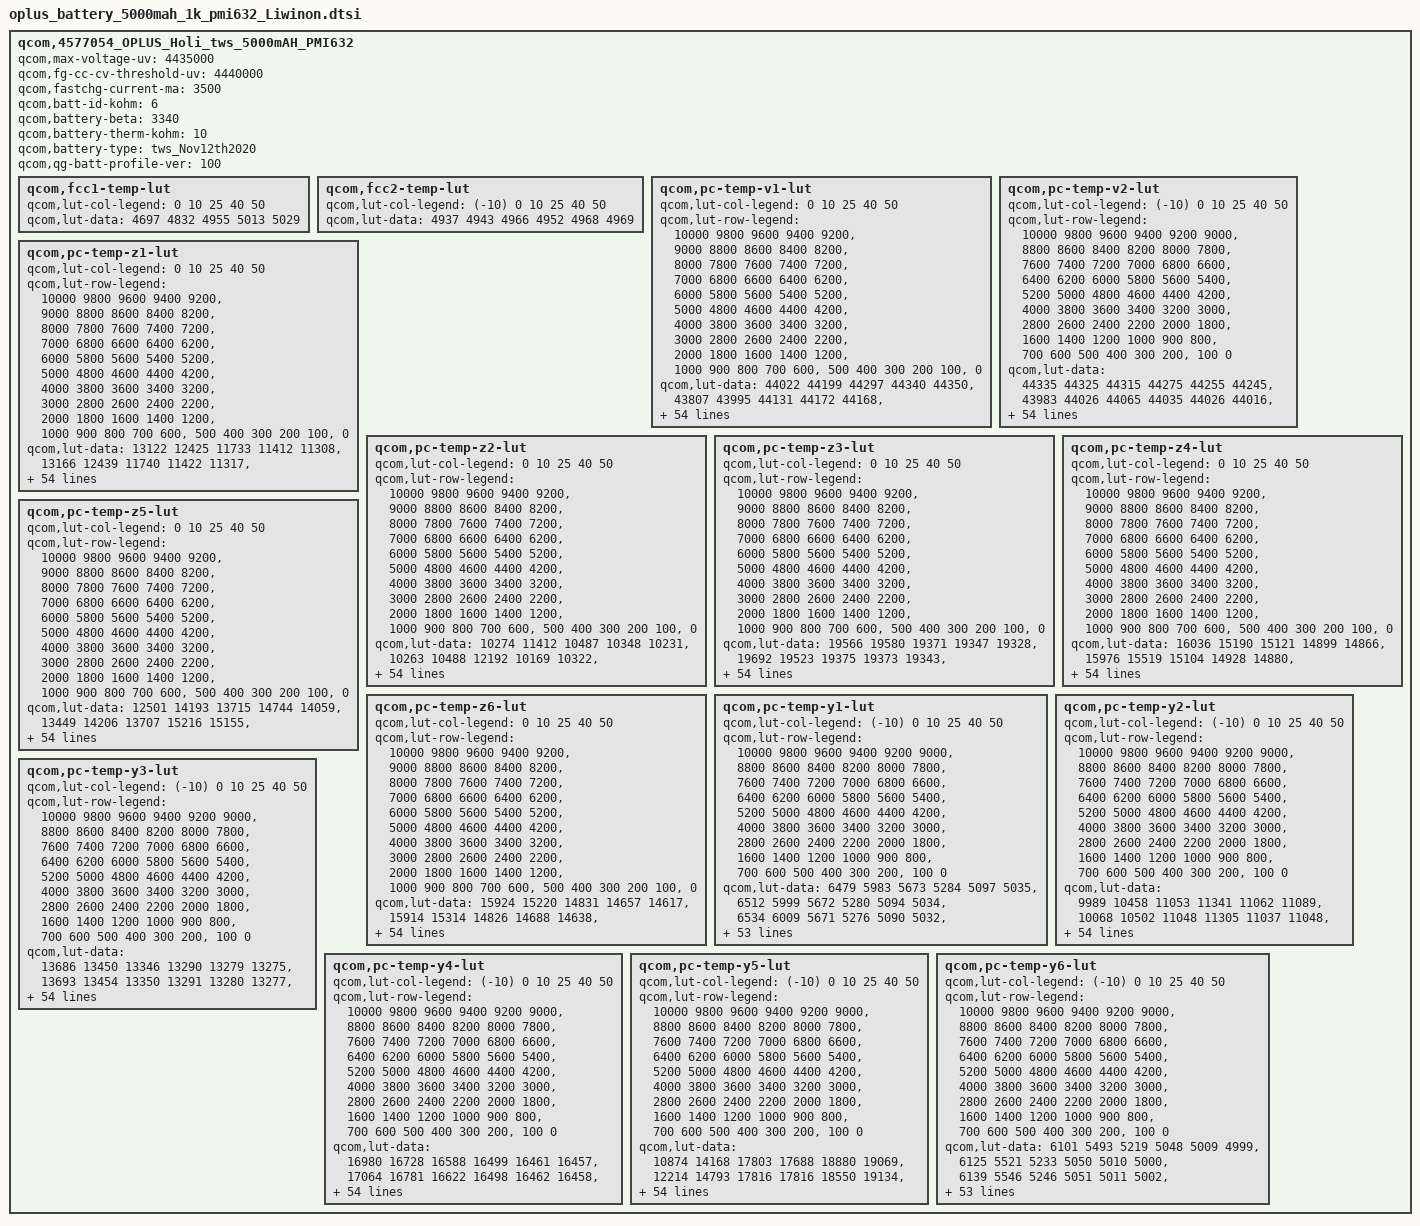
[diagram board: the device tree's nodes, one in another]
qcom,4577054_OPLUS_Holi_tws_5000mAH_PMI632 {
    /* 4577054_OPLUS_Holi_tws_5000mAH_PMI632_averaged_MasterSlave_Nov12th2020 */
    qcom,max-voltage-uv = <4435000>;
    qcom,fg-cc-cv-threshold-uv = <4440000>;
    qcom,fastchg-current-ma = <3500>;
    //qcom,batt-id-kohm = <1>;
    qcom,batt-id-kohm = <6>;
    qcom,battery-beta = <3340>;
    qcom,battery-therm-kohm = <10>;
    qcom,battery-type = "tws_Nov12th2020";
    qcom,qg-batt-profile-ver = <100>;
    //qcom,jeita-soft-thresholds_oplus = <0x5E68 0x72A>;
    //qcom,jeita-hard-thresholds_oplus = <0x5E68 0x72A>;

	qcom,fcc1-temp-lut {
		qcom,lut-col-legend = <0 10 25 40 50>;
		qcom,lut-data = <4697 4832 4955 5013 5029>;
	};

	qcom,fcc2-temp-lut {
		qcom,lut-col-legend = <(-10) 0 10 25 40 50>;
		qcom,lut-data = <4937 4943 4966 4952 4968 4969>;
	};

	qcom,pc-temp-v1-lut {
		qcom,lut-col-legend = <0 10 25 40 50>;
		qcom,lut-row-legend = <10000 9800 9600 9400 9200>,
			<9000 8800 8600 8400 8200>,
			<8000 7800 7600 7400 7200>,
			<7000 6800 6600 6400 6200>,
			<6000 5800 5600 5400 5200>,
			<5000 4800 4600 4400 4200>,
			<4000 3800 3600 3400 3200>,
			<3000 2800 2600 2400 2200>,
			<2000 1800 1600 1400 1200>,
			<1000 900 800 700 600>,
			<500 400 300 200 100>,
			<0>;
		qcom,lut-data = <44022 44199 44297 44340 44350>,
			<43807 43995 44131 44172 44168>,
			<43584 43790 43947 43979 43983>,
			<43355 43581 43746 43782 43791>,
			<43119 43359 43527 43585 43590>,
			<42881 43123 43299 43376 43379>,
			<42641 42883 43061 43145 43155>,
			<42401 42642 42818 42900 42918>,
			<42166 42398 42575 42654 42678>,
			<41935 42157 42330 42407 42433>,
			<41707 41919 42085 42162 42188>,
			<41482 41685 41841 41923 41947>,
			<41260 41458 41601 41688 41709>,
			<41046 41234 41369 41453 41474>,
			<40841 41018 41146 41217 41241>,
			<40640 40811 40929 40990 41014>,
			<40437 40609 40720 40777 40795>,
			<40232 40411 40517 40574 40583>,
			<40042 40219 40325 40378 40383>,
			<39879 40031 40142 40195 40203>,
			<39730 39855 39947 39996 40013>,
			<39579 39680 39733 39732 39759>,
			<39425 39471 39511 39437 39464>,
			<39270 39201 39272 39221 39244>,
			<39108 38966 39022 39063 39091>,
			<38937 38820 38851 38931 38962>,
			<38788 38707 38753 38816 38842>,
			<38674 38621 38674 38715 38735>,
			<38578 38554 38590 38616 38628>,
			<38504 38498 38508 38520 38520>,
			<38447 38444 38431 38430 38420>,
			<38400 38394 38358 38345 38332>,
			<38360 38347 38289 38266 38252>,
			<38328 38300 38226 38193 38177>,
			<38295 38256 38169 38126 38107>,
			<38261 38212 38114 38061 38037>,
			<38225 38171 38067 38002 37969>,
			<38178 38122 38019 37942 37899>,
			<38110 38051 37950 37866 37813>,
			<38026 37959 37855 37767 37707>,
			<37919 37854 37750 37658 37591>,
			<37780 37726 37637 37547 37476>,
			<37627 37580 37507 37421 37348>,
			<37461 37409 37341 37259 37187>,
			<37320 37251 37191 37117 37049>,
			<37230 37157 37090 37023 36967>,
			<37202 37125 37064 36999 36938>,
			<37168 37104 37048 36980 36922>,
			<37136 37081 37024 36962 36900>,
			<37075 37038 36978 36909 36838>,
			<36874 36827 36767 36668 36576>,
			<36420 36383 36333 36232 36138>,
			<35835 35810 35760 35661 35566>,
			<35044 35022 34978 34876 34781>,
			<33766 33770 33759 33655 33559>,
			<30000 30000 30000 30000 30000>;
	};

	qcom,pc-temp-v2-lut {
		qcom,lut-col-legend = <(-10) 0 10 25 40 50>;
		qcom,lut-row-legend = <10000 9800 9600 9400 9200 9000>,
			<8800 8600 8400 8200 8000 7800>,
			<7600 7400 7200 7000 6800 6600>,
			<6400 6200 6000 5800 5600 5400>,
			<5200 5000 4800 4600 4400 4200>,
			<4000 3800 3600 3400 3200 3000>,
			<2800 2600 2400 2200 2000 1800>,
			<1600 1400 1200 1000 900 800>,
			<700 600 500 400 300 200>,
			<100 0>;
		qcom,lut-data = <44335 44325 44315 44275 44255 44245>,
			<43983 44026 44065 44035 44026 44016>,
			<43662 43750 43827 43802 43801 43792>,
			<43376 43500 43600 43579 43583 43576>,
			<43124 43280 43388 43366 43372 43368>,
			<42877 43056 43170 43149 43157 43154>,
			<42611 42810 42933 42913 42924 42923>,
			<42344 42555 42687 42669 42683 42683>,
			<42106 42301 42439 42425 42442 42442>,
			<41897 42044 42189 42181 42197 42199>,
			<41688 41798 41942 41939 41954 41956>,
			<41456 41572 41701 41700 41716 41716>,
			<41214 41359 41465 41464 41481 41480>,
			<40973 41156 41237 41234 41250 41249>,
			<40742 40972 41018 41009 41022 41024>,
			<40492 40770 40806 40790 40801 40805>,
			<40175 40487 40610 40576 40589 40592>,
			<39812 40148 40417 40368 40384 40384>,
			<39522 39866 40190 40172 40187 40187>,
			<39305 39645 39907 39996 40004 40006>,
			<39109 39441 39629 39808 39809 39814>,
			<38899 39230 39396 39556 39559 39568>,
			<38690 39024 39185 39264 39283 39296>,
			<38523 38835 38999 39038 39068 39083>,
			<38391 38668 38834 38872 38901 38915>,
			<38283 38510 38686 38730 38758 38770>,
			<38202 38343 38552 38603 38630 38639>,
			<38137 38174 38429 38490 38517 38522>,
			<38078 38062 38317 38385 38412 38416>,
			<38022 38001 38214 38283 38313 38317>,
			<37969 37954 38117 38189 38223 38227>,
			<37911 37909 38016 38107 38144 38145>,
			<37851 37867 37917 38033 38071 38070>,
			<37787 37823 37845 37962 37995 37989>,
			<37720 37775 37797 37895 37915 37902>,
			<37649 37724 37755 37827 37829 37807>,
			<37574 37668 37712 37750 37730 37698>,
			<37493 37608 37671 37663 37620 37578>,
			<37410 37539 37617 37577 37519 37470>,
			<37324 37458 37541 37497 37431 37379>,
			<37238 37363 37449 37414 37343 37289>,
			<37164 37250 37340 37313 37242 37186>,
			<37098 37114 37210 37194 37130 37072>,
			<37029 36991 37061 37062 36998 36940>,
			<36957 36882 36915 36939 36888 36833>,
			<36865 36784 36814 36872 36834 36783>,
			<36812 36740 36780 36857 36821 36772>,
			<36748 36693 36739 36836 36807 36759>,
			<36682 36637 36691 36812 36784 36731>,
			<36584 36550 36606 36752 36706 36633>,
			<36399 36391 36405 36539 36436 36333>,
			<36037 36017 35990 36067 35942 35833>,
			<35451 35434 35367 35447 35304 35183>,
			<34586 34584 34515 34606 34428 34283>,
			<33250 33223 33225 33279 33073 32903>,
			<28411 28236 28170 28278 28339 28325>;
	};

	qcom,pc-temp-z1-lut {
		qcom,lut-col-legend = <0 10 25 40 50>;
		qcom,lut-row-legend = <10000 9800 9600 9400 9200>,
			<9000 8800 8600 8400 8200>,
			<8000 7800 7600 7400 7200>,
			<7000 6800 6600 6400 6200>,
			<6000 5800 5600 5400 5200>,
			<5000 4800 4600 4400 4200>,
			<4000 3800 3600 3400 3200>,
			<3000 2800 2600 2400 2200>,
			<2000 1800 1600 1400 1200>,
			<1000 900 800 700 600>,
			<500 400 300 200 100>,
			<0>;
		qcom,lut-data = <13122 12425 11733 11412 11308>,
			<13166 12439 11740 11422 11317>,
			<13187 12435 11742 11422 11324>,
			<13180 12430 11734 11420 11326>,
			<13161 12419 11720 11416 11323>,
			<13143 12398 11706 11410 11319>,
			<13125 12379 11694 11405 11316>,
			<13105 12367 11683 11399 11313>,
			<13080 12357 11672 11394 11312>,
			<13047 12341 11662 11390 11311>,
			<13023 12313 11654 11387 11310>,
			<13017 12288 11648 11384 11308>,
			<13014 12280 11643 11382 11306>,
			<13009 12275 11641 11381 11305>,
			<12986 12270 11639 11380 11304>,
			<12960 12260 11638 11379 11304>,
			<12948 12250 11637 11379 11304>,
			<12939 12247 11637 11378 11304>,
			<12932 12245 11637 11378 11304>,
			<12922 12245 11638 11379 11304>,
			<12907 12251 11639 11379 11304>,
			<12898 12261 11640 11379 11304>,
			<12893 12264 11641 11379 11304>,
			<12889 12260 11644 11380 11304>,
			<12893 12258 11649 11381 11305>,
			<12907 12262 11652 11384 11307>,
			<12917 12269 11655 11386 11309>,
			<12911 12272 11658 11388 11312>,
			<12898 12269 11662 11391 11315>,
			<12895 12266 11668 11395 11317>,
			<12902 12268 11673 11398 11320>,
			<12909 12274 11679 11402 11323>,
			<12910 12277 11684 11407 11326>,
			<12911 12281 11689 11410 11330>,
			<12913 12287 11693 11414 11333>,
			<12928 12294 11697 11417 11337>,
			<12953 12307 11703 11421 11340>,
			<12962 12316 11710 11424 11343>,
			<12958 12320 11716 11427 11346>,
			<12953 12324 11723 11431 11348>,
			<12965 12330 11729 11435 11350>,
			<13000 12346 11736 11439 11353>,
			<13011 12359 11744 11442 11355>,
			<13010 12368 11756 11447 11358>,
			<13005 12383 11770 11453 11362>,
			<13002 12399 11774 11455 11364>,
			<13004 12387 11774 11455 11363>,
			<13014 12392 11778 11454 11363>,
			<13015 12387 11782 11457 11364>,
			<13007 12400 11784 11461 11367>,
			<13015 12402 11799 11467 11372>,
			<13024 12433 11808 11473 11378>,
			<13033 12454 11823 11483 11386>,
			<13060 12481 11843 11495 11397>,
			<13060 12481 11843 11495 11397>,
			<13060 12481 11843 11495 11397>;
	};

	qcom,pc-temp-z2-lut {
		qcom,lut-col-legend = <0 10 25 40 50>;
		qcom,lut-row-legend = <10000 9800 9600 9400 9200>,
			<9000 8800 8600 8400 8200>,
			<8000 7800 7600 7400 7200>,
			<7000 6800 6600 6400 6200>,
			<6000 5800 5600 5400 5200>,
			<5000 4800 4600 4400 4200>,
			<4000 3800 3600 3400 3200>,
			<3000 2800 2600 2400 2200>,
			<2000 1800 1600 1400 1200>,
			<1000 900 800 700 600>,
			<500 400 300 200 100>,
			<0>;
		qcom,lut-data = <10274 11412 10487 10348 10231>,
			<10263 10488 12192 10169 10322>,
			<10250 10443 12944 10350 10385>,
			<10231 10422 12459 10653 10418>,
			<10209 10390 11419 11442 10438>,
			<10202 10345 10990 12041 10451>,
			<10206 10304 10871 11632 10444>,
			<10210 10272 10801 10719 10409>,
			<10209 10246 10843 10400 10379>,
			<10199 10230 10990 10357 10340>,
			<10185 10218 10986 10340 10293>,
			<10170 10212 10658 10691 10242>,
			<10152 10214 10375 11405 10188>,
			<10144 10220 10439 11530 10163>,
			<10142 10230 10647 10888 10148>,
			<10141 10255 10790 10369 10140>,
			<10142 10288 11029 10762 10152>,
			<10145 10313 11263 11557 10177>,
			<10151 10336 11367 11675 10201>,
			<10174 10355 11453 10891 10219>,
			<10214 10370 11457 10268 10247>,
			<10238 10384 11067 10421 10387>,
			<10248 10403 10653 10731 10648>,
			<10257 10435 10600 10772 10710>,
			<10270 10455 10588 10484 10479>,
			<10286 10453 10571 10262 10276>,
			<10301 10446 10519 10283 10289>,
			<10313 10444 10469 10331 10345>,
			<10323 10447 10483 10357 10428>,
			<10332 10452 10545 10370 10607>,
			<10340 10454 10586 10385 10736>,
			<10348 10456 10601 10440 10622>,
			<10356 10459 10610 10514 10370>,
			<10363 10463 10607 10523 10265>,
			<10372 10469 10594 10468 10227>,
			<10383 10475 10588 10421 10209>,
			<10395 10482 10592 10414 10246>,
			<10409 10490 10601 10425 10328>,
			<10426 10503 10620 10469 10388>,
			<10444 10519 10664 10590 10443>,
			<10461 10533 10693 10668 10472>,
			<10478 10544 10702 10655 10459>,
			<10505 10559 10706 10624 10441>,
			<10559 10583 10705 10562 10439>,
			<10916 10781 10750 10519 10435>,
			<10776 10821 10778 10507 10440>,
			<10673 10815 10748 10505 10418>,
			<10631 10824 10711 10462 10417>,
			<10528 10916 10711 10480 10427>,
			<10480 11089 10721 10608 10538>,
			<10490 10948 10820 10565 10445>,
			<10446 10985 10727 10331 10173>,
			<10207 10895 10690 10265 10126>,
			<10010 10826 10646 10224 10072>,
			<10010 10826 10646 10224 10072>,
			<10010 10826 10646 10224 10072>;
	};

	qcom,pc-temp-z3-lut {
		qcom,lut-col-legend = <0 10 25 40 50>;
		qcom,lut-row-legend = <10000 9800 9600 9400 9200>,
			<9000 8800 8600 8400 8200>,
			<8000 7800 7600 7400 7200>,
			<7000 6800 6600 6400 6200>,
			<6000 5800 5600 5400 5200>,
			<5000 4800 4600 4400 4200>,
			<4000 3800 3600 3400 3200>,
			<3000 2800 2600 2400 2200>,
			<2000 1800 1600 1400 1200>,
			<1000 900 800 700 600>,
			<500 400 300 200 100>,
			<0>;
		qcom,lut-data = <19566 19580 19371 19347 19328>,
			<19692 19523 19375 19373 19343>,
			<19774 19555 19385 19388 19365>,
			<19810 19604 19416 19405 19383>,
			<19834 19625 19465 19431 19394>,
			<19840 19638 19491 19447 19403>,
			<19833 19644 19503 19445 19409>,
			<19822 19644 19512 19440 19414>,
			<19812 19644 19523 19436 19416>,
			<19797 19643 19537 19434 19414>,
			<19788 19640 19538 19432 19411>,
			<19793 19636 19503 19437 19405>,
			<19803 19631 19468 19448 19395>,
			<19809 19623 19463 19448 19388>,
			<19808 19614 19467 19421 19385>,
			<19807 19603 19470 19399 19382>,
			<19808 19592 19475 19403 19379>,
			<19810 19581 19478 19411 19376>,
			<19812 19571 19474 19410 19371>,
			<19799 19566 19466 19385 19362>,
			<19774 19567 19460 19365 19356>,
			<19766 19569 19455 19376 19360>,
			<19766 19573 19451 19395 19372>,
			<19767 19588 19448 19398 19374>,
			<19769 19598 19446 19379 19353>,
			<19773 19596 19441 19360 19334>,
			<19776 19590 19428 19353 19331>,
			<19773 19583 19414 19348 19329>,
			<19766 19576 19413 19347 19333>,
			<19758 19569 19413 19353 19370>,
			<19750 19566 19414 19362 19400>,
			<19742 19563 19423 19376 19398>,
			<19732 19561 19435 19393 19392>,
			<19722 19561 19439 19396 19384>,
			<19713 19561 19441 19391 19374>,
			<19705 19560 19442 19385 19364>,
			<19697 19558 19436 19377 19358>,
			<19689 19555 19428 19370 19352>,
			<19682 19550 19425 19366 19349>,
			<19674 19543 19423 19365 19346>,
			<19665 19537 19420 19364 19345>,
			<19655 19531 19416 19362 19347>,
			<19641 19523 19411 19360 19351>,
			<19616 19510 19404 19359 19355>,
			<19511 19472 19390 19354 19354>,
			<19402 19453 19387 19350 19340>,
			<19328 19452 19383 19344 19338>,
			<19314 19440 19373 19342 19329>,
			<19304 19409 19375 19333 19324>,
			<19302 19345 19366 19325 19319>,
			<19306 19417 19359 19338 19339>,
			<19323 19402 19350 19363 19360>,
			<19326 19335 19349 19351 19353>,
			<19325 19318 19350 19352 19352>,
			<19325 19318 19350 19352 19352>,
			<19325 19318 19350 19352 19352>;
	};

	qcom,pc-temp-z4-lut {
		qcom,lut-col-legend = <0 10 25 40 50>;
		qcom,lut-row-legend = <10000 9800 9600 9400 9200>,
			<9000 8800 8600 8400 8200>,
			<8000 7800 7600 7400 7200>,
			<7000 6800 6600 6400 6200>,
			<6000 5800 5600 5400 5200>,
			<5000 4800 4600 4400 4200>,
			<4000 3800 3600 3400 3200>,
			<3000 2800 2600 2400 2200>,
			<2000 1800 1600 1400 1200>,
			<1000 900 800 700 600>,
			<500 400 300 200 100>,
			<0>;
		qcom,lut-data = <16036 15190 15121 14899 14866>,
			<15976 15519 15104 14928 14880>,
			<15891 15449 15076 14928 14879>,
			<15771 15328 15032 14919 14875>,
			<15617 15233 14974 14858 14856>,
			<15492 15149 14923 14803 14827>,
			<15399 15075 14879 14795 14805>,
			<15320 15017 14837 14791 14784>,
			<15254 14967 14786 14784 14764>,
			<15199 14924 14734 14767 14744>,
			<15147 14888 14721 14744 14729>,
			<15091 14857 14737 14708 14723>,
			<15035 14831 14752 14666 14720>,
			<14988 14808 14743 14658 14716>,
			<14949 14790 14716 14682 14709>,
			<14916 14773 14697 14701 14701>,
			<14890 14761 14673 14683 14695>,
			<14869 14758 14654 14648 14689>,
			<14850 14758 14650 14640 14684>,
			<14829 14757 14647 14656 14679>,
			<14809 14752 14648 14680 14676>,
			<14797 14743 14675 14715 14699>,
			<14789 14749 14717 14762 14758>,
			<14784 14803 14769 14797 14799>,
			<14789 14851 14834 14828 14825>,
			<14811 14862 14858 14844 14840>,
			<14831 14868 14854 14841 14836>,
			<14840 14869 14848 14832 14824>,
			<14847 14858 14839 14820 14803>,
			<14848 14842 14824 14800 14749>,
			<14843 14828 14805 14775 14703>,
			<14833 14814 14781 14744 14692>,
			<14824 14800 14757 14710 14685>,
			<14813 14786 14741 14698 14683>,
			<14801 14774 14727 14693 14683>,
			<14790 14765 14722 14692 14683>,
			<14779 14757 14722 14693 14684>,
			<14769 14753 14722 14698 14686>,
			<14758 14752 14725 14704 14692>,
			<14750 14752 14736 14718 14709>,
			<14745 14750 14742 14727 14722>,
			<14742 14741 14735 14723 14715>,
			<14736 14731 14727 14718 14706>,
			<14725 14723 14723 14718 14705>,
			<14711 14693 14702 14704 14693>,
			<14819 14682 14682 14685 14682>,
			<14896 14674 14675 14681 14676>,
			<14905 14673 14665 14667 14667>,
			<14909 14696 14647 14652 14648>,
			<14906 14764 14650 14648 14639>,
			<14901 14688 14680 14670 14660>,
			<14902 14723 14709 14663 14658>,
			<14911 14803 14712 14679 14667>,
			<14928 14829 14715 14679 14669>,
			<14928 14829 14715 14679 14669>,
			<14928 14829 14715 14679 14669>;
	};

	qcom,pc-temp-z5-lut {
		qcom,lut-col-legend = <0 10 25 40 50>;
		qcom,lut-row-legend = <10000 9800 9600 9400 9200>,
			<9000 8800 8600 8400 8200>,
			<8000 7800 7600 7400 7200>,
			<7000 6800 6600 6400 6200>,
			<6000 5800 5600 5400 5200>,
			<5000 4800 4600 4400 4200>,
			<4000 3800 3600 3400 3200>,
			<3000 2800 2600 2400 2200>,
			<2000 1800 1600 1400 1200>,
			<1000 900 800 700 600>,
			<500 400 300 200 100>,
			<0>;
		qcom,lut-data = <12501 14193 13715 14744 14059>,
			<13449 14206 13707 15216 15155>,
			<14131 14765 13706 16459 16683>,
			<14504 15616 14407 17651 17946>,
			<14766 16161 16057 18956 18846>,
			<14982 16563 17288 19933 19642>,
			<15186 16969 18156 20288 20417>,
			<15368 17428 19190 20516 21251>,
			<15515 17937 21598 20846 22004>,
			<15629 18537 25001 21287 22947>,
			<15779 19287 25766 22021 23645>,
			<16237 20126 23141 26322 23380>,
			<17083 20996 20751 33719 22540>,
			<17904 21932 21700 35028 22272>,
			<18612 22964 24750 28985 23047>,
			<19426 24406 27160 24103 24150>,
			<20690 25618 31987 28194 25347>,
			<22735 25865 36512 36385 26817>,
			<24551 25914 37744 37621 27270>,
			<25483 26005 38410 29914 26890>,
			<26212 28031 39385 23821 26529>,
			<27566 32482 41402 31945 30181>,
			<31340 38450 43012 47580 38792>,
			<36434 49104 42247 49740 40678>,
			<41704 56459 39210 35328 29804>,
			<48065 53844 35579 22569 19233>,
			<51562 46704 29645 19380 17040>,
			<50968 41180 24083 17475 15853>,
			<49442 37070 22226 17145 16113>,
			<47878 34203 21185 17257 20839>,
			<45819 33307 20909 17475 25546>,
			<43536 32796 22474 19717 27193>,
			<41530 32633 25250 24024 28255>,
			<39506 33931 28626 26910 28584>,
			<38361 36270 33203 29232 28395>,
			<38143 38356 35378 30483 28092>,
			<38044 40660 35598 30209 27894>,
			<38182 41937 35690 29383 27674>,
			<39573 41822 35438 28691 27159>,
			<41023 41458 34292 27874 25530>,
			<41070 40873 32783 26766 23950>,
			<40558 39383 30506 24371 23039>,
			<39965 37584 28259 22361 22547>,
			<38680 35463 26595 22205 23577>,
			<30183 37694 27584 22550 24510>,
			<18861 33299 29059 22544 20651>,
			<12762 32749 27620 20847 20300>,
			<12425 27583 25123 21709 19081>,
			<12211 21663 28916 21956 21390>,
			<12200 14605 26034 21343 22627>,
			<12376 22094 20005 20260 22898>,
			<12620 17934 15947 21307 22996>,
			<12470 13314 15396 17103 18838>,
			<12230 12539 14898 16336 17087>,
			<12230 12539 14898 16336 17087>,
			<12230 12539 14898 16336 17087>;
	};

	qcom,pc-temp-z6-lut {
		qcom,lut-col-legend = <0 10 25 40 50>;
		qcom,lut-row-legend = <10000 9800 9600 9400 9200>,
			<9000 8800 8600 8400 8200>,
			<8000 7800 7600 7400 7200>,
			<7000 6800 6600 6400 6200>,
			<6000 5800 5600 5400 5200>,
			<5000 4800 4600 4400 4200>,
			<4000 3800 3600 3400 3200>,
			<3000 2800 2600 2400 2200>,
			<2000 1800 1600 1400 1200>,
			<1000 900 800 700 600>,
			<500 400 300 200 100>,
			<0>;
		qcom,lut-data = <15924 15220 14831 14657 14617>,
			<15914 15314 14826 14688 14638>,
			<15890 15287 14820 14698 14650>,
			<15840 15239 14815 14698 14653>,
			<15755 15197 14809 14688 14650>,
			<15678 15154 14801 14676 14645>,
			<15615 15114 14786 14669 14639>,
			<15558 15080 14769 14663 14633>,
			<15510 15049 14754 14656 14625>,
			<15467 15022 14739 14647 14617>,
			<15429 14998 14726 14637 14608>,
			<15398 14977 14713 14627 14601>,
			<15370 14958 14701 14616 14594>,
			<15345 14940 14692 14609 14588>,
			<15320 14924 14684 14604 14582>,
			<15298 14909 14677 14598 14577>,
			<15281 14896 14670 14592 14572>,
			<15268 14889 14664 14584 14567>,
			<15254 14883 14658 14578 14562>,
			<15232 14879 14653 14572 14555>,
			<15208 14878 14652 14569 14550>,
			<15198 14877 14660 14587 14564>,
			<15196 14882 14674 14622 14598>,
			<15194 14914 14694 14633 14610>,
			<15198 14941 14721 14635 14610>,
			<15212 14943 14731 14636 14609>,
			<15223 14943 14724 14633 14606>,
			<15225 14943 14715 14626 14600>,
			<15226 14936 14708 14621 14595>,
			<15226 14926 14703 14616 14592>,
			<15220 14919 14698 14611 14588>,
			<15212 14912 14694 14606 14584>,
			<15204 14907 14690 14601 14578>,
			<15195 14902 14687 14597 14573>,
			<15188 14898 14683 14593 14568>,
			<15181 14895 14681 14590 14563>,
			<15175 14893 14677 14587 14560>,
			<15172 14892 14675 14585 14558>,
			<15170 14892 14676 14585 14559>,
			<15169 14892 14680 14590 14564>,
			<15169 14892 14683 14594 14568>,
			<15170 14889 14679 14592 14567>,
			<15169 14886 14674 14589 14566>,
			<15163 14881 14671 14589 14567>,
			<15120 14861 14658 14581 14562>,
			<15113 14849 14649 14572 14550>,
			<15107 14845 14644 14566 14547>,
			<15104 14840 14635 14559 14538>,
			<15102 14836 14629 14548 14527>,
			<15106 14836 14627 14542 14520>,
			<15114 14846 14639 14560 14541>,
			<15133 14859 14650 14572 14554>,
			<15150 14868 14654 14576 14557>,
			<15176 14883 14661 14579 14561>,
			<15176 14883 14661 14579 14561>,
			<15176 14883 14661 14579 14561>;
	};

	qcom,pc-temp-y1-lut {
		qcom,lut-col-legend = <(-10) 0 10 25 40 50>;
		qcom,lut-row-legend = <10000 9800 9600 9400 9200 9000>,
			<8800 8600 8400 8200 8000 7800>,
			<7600 7400 7200 7000 6800 6600>,
			<6400 6200 6000 5800 5600 5400>,
			<5200 5000 4800 4600 4400 4200>,
			<4000 3800 3600 3400 3200 3000>,
			<2800 2600 2400 2200 2000 1800>,
			<1600 1400 1200 1000 900 800>,
			<700 600 500 400 300 200>,
			<100 0>;
		qcom,lut-data = <6479 5983 5673 5284 5097 5035>,
			<6512 5999 5672 5280 5094 5034>,
			<6534 6009 5671 5276 5090 5032>,
			<6545 6017 5668 5271 5087 5031>,
			<6551 6021 5666 5267 5084 5030>,
			<6552 6025 5664 5263 5082 5029>,
			<6543 6025 5663 5259 5081 5029>,
			<6529 6022 5662 5256 5080 5028>,
			<6525 6020 5658 5251 5078 5027>,
			<6525 6017 5643 5246 5076 5026>,
			<6525 6014 5631 5242 5074 5026>,
			<6531 6015 5631 5241 5073 5025>,
			<6545 6017 5632 5241 5072 5025>,
			<6548 6016 5633 5240 5071 5024>,
			<6529 6008 5636 5238 5070 5022>,
			<6512 6001 5639 5236 5069 5020>,
			<6517 6006 5634 5236 5069 5021>,
			<6530 6016 5625 5236 5069 5022>,
			<6535 6021 5623 5236 5069 5022>,
			<6538 6023 5633 5237 5069 5022>,
			<6541 6025 5642 5238 5068 5022>,
			<6533 6023 5641 5240 5069 5022>,
			<6513 6019 5638 5243 5070 5023>,
			<6502 6020 5638 5245 5071 5023>,
			<6497 6025 5639 5247 5071 5024>,
			<6494 6028 5641 5249 5072 5025>,
			<6487 6028 5642 5252 5074 5025>,
			<6471 6025 5643 5256 5076 5026>,
			<6464 6025 5646 5260 5078 5028>,
			<6477 6027 5652 5264 5080 5030>,
			<6492 6028 5659 5269 5083 5032>,
			<6490 6026 5663 5273 5086 5034>,
			<6478 6018 5665 5278 5089 5036>,
			<6470 6015 5667 5283 5091 5038>,
			<6468 6023 5665 5289 5094 5040>,
			<6470 6032 5663 5293 5096 5042>,
			<6473 6033 5667 5297 5098 5044>,
			<6480 6029 5679 5299 5100 5045>,
			<6483 6026 5686 5302 5101 5046>,
			<6478 6016 5692 5306 5104 5048>,
			<6468 6002 5696 5310 5106 5049>,
			<6457 5996 5693 5314 5107 5051>,
			<6444 5984 5686 5317 5108 5052>,
			<6439 5988 5682 5321 5111 5054>,
			<6452 6006 5687 5328 5114 5056>,
			<6451 6014 5702 5338 5118 5058>,
			<6437 6019 5693 5340 5118 5057>,
			<6465 5992 5708 5338 5118 5058>,
			<6465 6032 5692 5339 5117 5058>,
			<6463 6021 5693 5338 5116 5058>,
			<6459 6019 5694 5342 5118 5060>,
			<6521 6015 5706 5343 5124 5064>,
			<6592 6008 5722 5366 5130 5070>,
			<6680 6055 5735 5381 5138 5075>,
			<6680 6055 5735 5381 5138 5075>,
			<6680 6055 5735 5381 5138 5075>;
	};

	qcom,pc-temp-y2-lut {
		qcom,lut-col-legend = <(-10) 0 10 25 40 50>;
		qcom,lut-row-legend = <10000 9800 9600 9400 9200 9000>,
			<8800 8600 8400 8200 8000 7800>,
			<7600 7400 7200 7000 6800 6600>,
			<6400 6200 6000 5800 5600 5400>,
			<5200 5000 4800 4600 4400 4200>,
			<4000 3800 3600 3400 3200 3000>,
			<2800 2600 2400 2200 2000 1800>,
			<1600 1400 1200 1000 900 800>,
			<700 600 500 400 300 200>,
			<100 0>;
		qcom,lut-data = <9989 10458 11053 11341 11062 11089>,
			<10068 10502 11048 11305 11037 11048>,
			<10146 10569 11039 11248 11003 10978>,
			<10219 10643 11027 11186 10965 10900>,
			<10282 10705 11015 11130 10928 10833>,
			<10330 10737 11004 11096 10898 10801>,
			<10359 10745 10991 11075 10866 10796>,
			<10383 10750 10977 11057 10837 10793>,
			<10444 10751 10974 11053 10828 10789>,
			<10625 10748 10974 11052 10825 10777>,
			<10757 10745 10975 11054 10828 10769>,
			<10728 10826 10988 11065 10852 10767>,
			<10664 10984 11016 11087 10893 10763>,
			<10657 11023 11044 11115 10924 10764>,
			<10774 10955 11072 11162 10949 10777>,
			<10877 10896 11108 11209 10977 10791>,
			<10608 10923 11179 11241 11014 10815>,
			<9973 10997 11264 11270 11065 10862>,
			<9732 11052 11281 11325 11140 10930>,
			<9714 11089 11253 11471 11282 11080>,
			<9704 11118 11230 11586 11379 11186>,
			<9694 11141 11232 11519 11310 11141>,
			<9685 11162 11239 11357 11168 11046>,
			<9680 11163 11249 11302 11124 11021>,
			<9677 11079 11266 11327 11132 11042>,
			<9675 10992 11287 11361 11146 11073>,
			<9673 10990 11310 11385 11185 11107>,
			<9671 11001 11333 11410 11255 11150>,
			<9669 11005 11340 11439 11292 11207>,
			<9668 10966 11338 11480 11300 11304>,
			<9667 10881 11335 11519 11312 11371>,
			<9666 10626 11326 11545 11391 11368>,
			<9665 10045 11308 11567 11535 11356>,
			<9665 9743 11286 11576 11589 11358>,
			<9664 9709 11258 11577 11581 11435>,
			<9663 9690 11227 11575 11559 11508>,
			<9663 9680 11203 11554 11482 11461>,
			<9663 9673 11182 11498 11326 11330>,
			<9663 9669 11148 11464 11259 11261>,
			<9662 9666 11076 11455 11248 11240>,
			<9662 9664 10984 11448 11243 11231>,
			<9662 9663 10901 11431 11263 11212>,
			<9662 9662 10800 11397 11301 11164>,
			<9662 9661 10424 11358 11229 11084>,
			<9661 9660 9947 11297 11070 10954>,
			<9660 9659 9830 11189 10991 10859>,
			<9660 9659 9837 11228 11020 10846>,
			<9659 9659 9787 11196 11051 10927>,
			<9659 9658 9739 11199 11118 10949>,
			<9658 9658 9720 11215 11091 10907>,
			<9656 9657 9706 11206 11010 10796>,
			<9653 9656 9685 11107 10900 10739>,
			<9651 9655 9669 11009 10843 10677>,
			<9649 9652 9660 10902 10769 10542>,
			<9649 9652 9660 10902 10769 10542>,
			<9649 9652 9660 10902 10769 10542>;
	};

	qcom,pc-temp-y3-lut {
		qcom,lut-col-legend = <(-10) 0 10 25 40 50>;
		qcom,lut-row-legend = <10000 9800 9600 9400 9200 9000>,
			<8800 8600 8400 8200 8000 7800>,
			<7600 7400 7200 7000 6800 6600>,
			<6400 6200 6000 5800 5600 5400>,
			<5200 5000 4800 4600 4400 4200>,
			<4000 3800 3600 3400 3200 3000>,
			<2800 2600 2400 2200 2000 1800>,
			<1600 1400 1200 1000 900 800>,
			<700 600 500 400 300 200>,
			<100 0>;
		qcom,lut-data = <13686 13450 13346 13290 13279 13275>,
			<13693 13454 13350 13291 13280 13277>,
			<13695 13459 13354 13294 13281 13278>,
			<13692 13465 13358 13296 13282 13279>,
			<13686 13469 13362 13298 13283 13281>,
			<13678 13471 13365 13299 13284 13282>,
			<13664 13471 13367 13299 13285 13283>,
			<13649 13470 13369 13299 13287 13283>,
			<13643 13468 13370 13300 13287 13284>,
			<13642 13460 13369 13302 13288 13285>,
			<13641 13454 13368 13304 13289 13286>,
			<13604 13462 13365 13305 13291 13286>,
			<13531 13478 13360 13307 13295 13287>,
			<13511 13479 13359 13308 13296 13288>,
			<13517 13447 13359 13310 13296 13290>,
			<13523 13417 13359 13311 13296 13292>,
			<13509 13413 13360 13308 13297 13292>,
			<13476 13411 13360 13302 13298 13292>,
			<13465 13407 13359 13300 13299 13292>,
			<13467 13402 13351 13306 13297 13293>,
			<13470 13395 13343 13311 13294 13293>,
			<13472 13387 13338 13308 13290 13290>,
			<13474 13379 13335 13300 13285 13283>,
			<13474 13371 13332 13295 13282 13281>,
			<13468 13366 13330 13293 13281 13280>,
			<13461 13359 13328 13291 13281 13280>,
			<13468 13348 13327 13292 13281 13279>,
			<13496 13333 13325 13293 13281 13278>,
			<13529 13327 13324 13293 13281 13278>,
			<13563 13329 13322 13292 13280 13279>,
			<13603 13333 13320 13292 13279 13280>,
			<13643 13341 13319 13292 13280 13279>,
			<13686 13356 13318 13292 13282 13279>,
			<13731 13375 13318 13293 13283 13279>,
			<13780 13396 13319 13293 13282 13279>,
			<13828 13423 13321 13293 13282 13280>,
			<13874 13459 13324 13293 13282 13279>,
			<13918 13507 13328 13292 13280 13278>,
			<13957 13564 13331 13292 13280 13278>,
			<13990 13634 13334 13292 13281 13279>,
			<14020 13711 13336 13293 13282 13281>,
			<14052 13783 13340 13293 13282 13281>,
			<14084 13851 13344 13294 13283 13281>,
			<14125 13918 13348 13295 13281 13280>,
			<14179 13983 13354 13296 13280 13279>,
			<14245 14035 13364 13300 13285 13284>,
			<14201 13993 13363 13302 13288 13287>,
			<14269 14057 13378 13303 13293 13291>,
			<14372 14124 13408 13312 13297 13293>,
			<14520 14200 13438 13315 13297 13291>,
			<14729 14297 13466 13313 13291 13286>,
			<15456 14409 13510 13309 13288 13286>,
			<17202 14710 13623 13314 13292 13289>,
			<21465 15735 13904 13323 13300 13295>,
			<21465 15735 13904 13323 13300 13295>,
			<21465 15735 13904 13323 13300 13295>;
	};

	qcom,pc-temp-y4-lut {
		qcom,lut-col-legend = <(-10) 0 10 25 40 50>;
		qcom,lut-row-legend = <10000 9800 9600 9400 9200 9000>,
			<8800 8600 8400 8200 8000 7800>,
			<7600 7400 7200 7000 6800 6600>,
			<6400 6200 6000 5800 5600 5400>,
			<5200 5000 4800 4600 4400 4200>,
			<4000 3800 3600 3400 3200 3000>,
			<2800 2600 2400 2200 2000 1800>,
			<1600 1400 1200 1000 900 800>,
			<700 600 500 400 300 200>,
			<100 0>;
		qcom,lut-data = <16980 16728 16588 16499 16461 16457>,
			<17064 16781 16622 16498 16462 16458>,
			<17172 16871 16667 16498 16463 16460>,
			<17279 16971 16712 16499 16465 16461>,
			<17362 17053 16747 16501 16466 16462>,
			<17398 17089 16762 16504 16468 16463>,
			<17389 17084 16757 16507 16469 16463>,
			<17369 17076 16748 16512 16471 16464>,
			<17348 17074 16744 16515 16473 16465>,
			<17322 17077 16743 16519 16477 16467>,
			<17306 17080 16742 16523 16481 16470>,
			<17352 17069 16751 16528 16483 16474>,
			<17448 17049 16771 16535 16485 16479>,
			<17467 17053 16788 16543 16489 16483>,
			<17374 17144 16802 16553 16497 16486>,
			<17255 17223 16817 16568 16507 16490>,
			<17170 17160 16834 16593 16517 16497>,
			<17092 17003 16850 16627 16528 16508>,
			<17026 16917 16846 16647 16545 16522>,
			<16975 16886 16777 16660 16578 16546>,
			<16925 16860 16702 16667 16601 16562>,
			<16860 16824 16662 16630 16572 16543>,
			<16787 16783 16630 16542 16511 16500>,
			<16762 16745 16611 16504 16484 16478>,
			<16766 16713 16598 16497 16474 16468>,
			<16771 16682 16590 16494 16470 16463>,
			<16772 16645 16586 16495 16472 16465>,
			<16774 16606 16583 16501 16479 16471>,
			<16776 16592 16581 16507 16486 16477>,
			<16776 16599 16578 16514 16498 16485>,
			<16777 16613 16574 16522 16510 16493>,
			<16779 16632 16560 16532 16521 16506>,
			<16783 16664 16534 16543 16532 16519>,
			<16786 16692 16527 16549 16535 16523>,
			<16787 16713 16538 16551 16534 16521>,
			<16789 16731 16556 16552 16530 16518>,
			<16788 16745 16577 16544 16518 16507>,
			<16783 16757 16603 16519 16494 16489>,
			<16781 16762 16625 16508 16484 16482>,
			<16785 16761 16647 16508 16483 16481>,
			<16795 16758 16662 16508 16483 16480>,
			<16806 16751 16664 16510 16483 16481>,
			<16823 16734 16664 16514 16485 16482>,
			<16849 16725 16662 16512 16476 16469>,
			<16882 16721 16662 16506 16466 16456>,
			<16896 16738 16668 16513 16474 16469>,
			<16833 16726 16666 16511 16489 16491>,
			<16841 16746 16694 16533 16513 16521>,
			<16860 16787 16737 16560 16546 16553>,
			<16874 16830 16785 16588 16555 16553>,
			<16884 16851 16808 16570 16506 16494>,
			<16975 16826 16807 16520 16476 16472>,
			<17326 16810 16818 16532 16478 16472>,
			<18874 17091 16877 16561 16487 16480>,
			<18874 17091 16877 16561 16487 16480>,
			<18874 17091 16877 16561 16487 16480>;
	};

	qcom,pc-temp-y5-lut {
		qcom,lut-col-legend = <(-10) 0 10 25 40 50>;
		qcom,lut-row-legend = <10000 9800 9600 9400 9200 9000>,
			<8800 8600 8400 8200 8000 7800>,
			<7600 7400 7200 7000 6800 6600>,
			<6400 6200 6000 5800 5600 5400>,
			<5200 5000 4800 4600 4400 4200>,
			<4000 3800 3600 3400 3200 3000>,
			<2800 2600 2400 2200 2000 1800>,
			<1600 1400 1200 1000 900 800>,
			<700 600 500 400 300 200>,
			<100 0>;
		qcom,lut-data = <10874 14168 17803 17688 18880 19069>,
			<12214 14793 17816 17816 18550 19134>,
			<13552 15522 17822 17723 18141 19078>,
			<14804 16246 17824 17463 17706 18925>,
			<15883 16855 17823 17091 17298 18702>,
			<16704 17239 17822 16658 16973 18431>,
			<17197 17439 17839 16013 16716 18079>,
			<17594 17570 17843 15292 16458 17659>,
			<18422 17551 17719 14997 16151 17268>,
			<20427 17236 17270 14953 15727 16900>,
			<21834 16988 16739 14965 15484 16520>,
			<20708 17883 16178 14913 15837 16014>,
			<18380 19652 15650 14803 16465 15530>,
			<18084 20096 15571 14714 16517 15497>,
			<22027 19489 15894 14639 15786 15972>,
			<25508 18968 16460 14536 15147 16334>,
			<23162 19156 18444 14221 14993 15870>,
			<17459 19751 21464 13747 14901 14993>,
			<15521 20445 22247 14003 14903 14780>,
			<16187 21458 22180 18013 15096 14963>,
			<16833 22297 22108 21587 15441 15298>,
			<16651 22538 22108 21555 16630 16575>,
			<15904 22679 22172 21078 18519 18624>,
			<15012 22899 22220 20544 18990 19183>,
			<13623 23646 22255 19514 18405 19027>,
			<12481 24334 22287 18678 17734 18744>,
			<12377 22340 22343 18841 17395 17856>,
			<12442 16464 22467 19380 17133 16418>,
			<12548 13900 22701 19570 16768 15970>,
			<12825 13970 23510 19186 16130 15972>,
			<13168 14064 24185 18775 15679 15987>,
			<13390 14063 23832 18926 16120 16020>,
			<13576 13940 22770 19609 17329 16104>,
			<13731 13905 21781 20398 18285 16313>,
			<13887 14066 20753 21563 19066 17430>,
			<14017 14331 19997 22520 19578 18550>,
			<14057 14657 19812 22474 19679 18873>,
			<14032 15113 19729 21927 19733 19079>,
			<13962 15488 19559 21265 19728 19325>,
			<13580 15835 18982 20370 19491 20070>,
			<13091 16121 18477 19478 19258 20720>,
			<13025 15940 18526 18994 19286 20791>,
			<13122 15073 18714 18658 19373 20701>,
			<13194 14690 17887 18526 18521 19891>,
			<13302 14496 15879 18291 17092 18426>,
			<13469 14007 14740 17635 16271 17114>,
			<13690 13974 14569 18109 16360 16830>,
			<13716 14056 14361 16956 17167 16957>,
			<14057 14186 14778 18034 17572 16640>,
			<14412 14461 15458 18498 17255 15826>,
			<14105 15367 15679 18826 16791 15898>,
			<12717 14374 15043 19704 16648 16503>,
			<10916 13717 14098 19650 17254 16508>,
			<9712 11626 13567 20358 22581 20658>,
			<9712 11626 13567 20358 22581 20658>,
			<9712 11626 13567 20358 22581 20658>;
	};

	qcom,pc-temp-y6-lut {
		qcom,lut-col-legend = <(-10) 0 10 25 40 50>;
		qcom,lut-row-legend = <10000 9800 9600 9400 9200 9000>,
			<8800 8600 8400 8200 8000 7800>,
			<7600 7400 7200 7000 6800 6600>,
			<6400 6200 6000 5800 5600 5400>,
			<5200 5000 4800 4600 4400 4200>,
			<4000 3800 3600 3400 3200 3000>,
			<2800 2600 2400 2200 2000 1800>,
			<1600 1400 1200 1000 900 800>,
			<700 600 500 400 300 200>,
			<100 0>;
		qcom,lut-data = <6101 5493 5219 5048 5009 4999>,
			<6125 5521 5233 5050 5010 5000>,
			<6139 5546 5246 5051 5011 5002>,
			<6147 5568 5256 5053 5012 5003>,
			<6149 5583 5263 5054 5013 5005>,
			<6150 5589 5265 5055 5014 5006>,
			<6138 5585 5263 5056 5015 5007>,
			<6114 5576 5259 5057 5017 5007>,
			<6101 5568 5254 5058 5018 5008>,
			<6094 5559 5250 5060 5019 5010>,
			<6087 5554 5247 5062 5021 5011>,
			<6075 5554 5247 5064 5023 5012>,
			<6059 5555 5247 5067 5026 5014>,
			<6043 5557 5247 5070 5028 5016>,
			<6027 5561 5250 5074 5030 5019>,
			<6007 5564 5254 5078 5033 5021>,
			<5967 5546 5258 5083 5036 5024>,
			<5910 5502 5262 5088 5040 5026>,
			<5880 5476 5261 5094 5045 5030>,
			<5869 5466 5236 5101 5053 5037>,
			<5861 5457 5208 5106 5058 5042>,
			<5851 5446 5194 5093 5047 5034>,
			<5840 5434 5182 5062 5025 5016>,
			<5837 5425 5176 5048 5015 5008>,
			<5843 5420 5172 5045 5011 5004>,
			<5855 5416 5170 5043 5010 5003>,
			<5872 5410 5170 5044 5011 5003>,
			<5900 5402 5170 5047 5013 5004>,
			<5930 5400 5170 5049 5015 5006>,
			<5961 5418 5171 5052 5018 5008>,
			<5994 5447 5172 5054 5021 5012>,
			<6029 5476 5171 5057 5025 5015>,
			<6066 5510 5167 5061 5030 5019>,
			<6103 5548 5166 5064 5031 5020>,
			<6142 5591 5175 5066 5031 5020>,
			<6181 5641 5188 5067 5030 5019>,
			<6217 5696 5203 5065 5026 5017>,
			<6250 5758 5222 5059 5019 5010>,
			<6281 5823 5244 5055 5016 5008>,
			<6308 5892 5268 5056 5016 5009>,
			<6334 5962 5295 5057 5017 5010>,
			<6363 6024 5323 5060 5018 5011>,
			<6394 6081 5354 5063 5019 5011>,
			<6435 6137 5384 5064 5016 5007>,
			<6490 6192 5419 5066 5012 5003>,
			<6552 6244 5441 5072 5019 5011>,
			<6510 6211 5434 5072 5025 5020>,
			<6570 6267 5472 5080 5036 5031>,
			<6663 6338 5524 5094 5048 5041>,
			<6789 6412 5573 5105 5050 5040>,
			<6967 6498 5618 5098 5032 5020>,
			<7627 6591 5678 5083 5022 5014>,
			<9132 6836 5825 5094 5027 5017>,
			<12735 7771 6109 5114 5037 5025>,
			<12735 7771 6109 5114 5037 5025>,
			<12735 7771 6109 5114 5037 5025>;
	};

};
